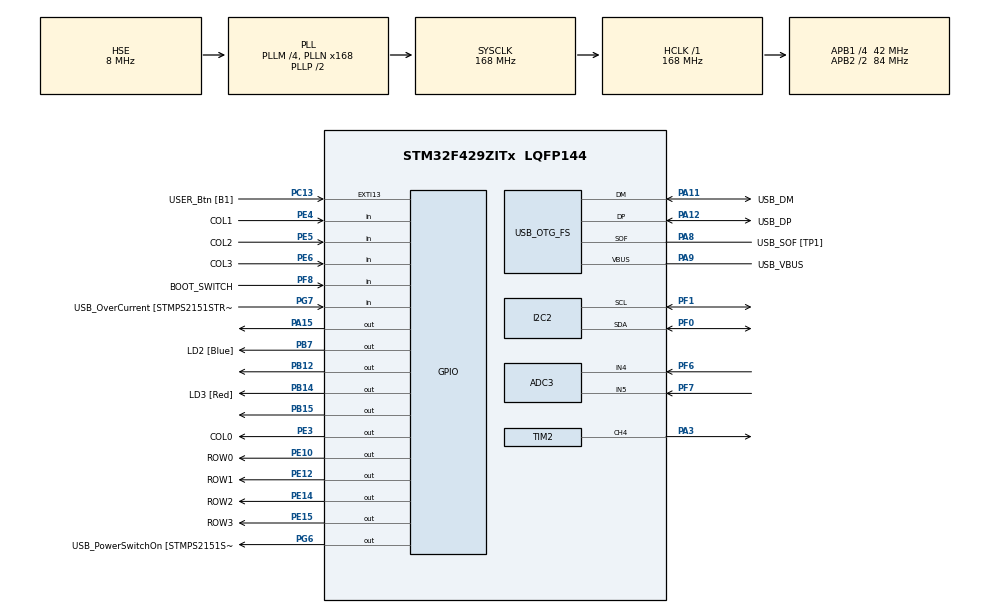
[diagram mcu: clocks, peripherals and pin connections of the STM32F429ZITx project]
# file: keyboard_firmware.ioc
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ADC3.Channel-0\#ChannelRegularConversion=ADC_CHANNEL_5
ADC3.NbrOfConversionFlag=1
ADC3.Rank-0\#ChannelRegularConversion=1
ADC3.SamplingTime-0\#ChannelRegularConversion=ADC_SAMPLETIME_3CYCLES
Dma.Request0=TIM2_CH2/CH4
Dma.TIM2_CH2/CH4.0.Direction=DMA_MEMORY_TO_PERIPH
Dma.TIM2_CH2/CH4.0.FIFOMode=DMA_FIFOMODE_DISABLE
Dma.TIM2_CH2/CH4.0.Instance=DMA1_Stream6
Dma.TIM2_CH2/CH4.0.MemDataAlignment=DMA_MDATAALIGN_WORD
Dma.TIM2_CH2/CH4.0.MemInc=DMA_MINC_ENABLE
Dma.TIM2_CH2/CH4.0.Mode=DMA_CIRCULAR
Dma.TIM2_CH2/CH4.0.PeriphDataAlignment=DMA_PDATAALIGN_WORD
Dma.TIM2_CH2/CH4.0.PeriphInc=DMA_PINC_DISABLE
Dma.TIM2_CH2/CH4.0.Priority=DMA_PRIORITY_MEDIUM
FREERTOS.INCLUDE_vTaskDelayUntil=1
FREERTOS.Tasks01=defaultTask,0,128,StartDefaultTask,Default,NULL,Dynamic,NULL,NULL
FREERTOS.configUSE_NEWLIB_REENTRANT=1
FREERTOS.configUSE_TIMERS=1
Mcu.Family=STM32F4
Mcu.Name=STM32F429ZITx
Mcu.Package=LQFP144
NVIC.DMA1_Stream6_IRQn=true\:5\:0\:false\:false\:true\:true\:false\:true\:true
NVIC.OTG_FS_IRQn=true\:5\:0\:false\:false\:true\:true\:true\:true\:true
NVIC.PriorityGroup=NVIC_PRIORITYGROUP_4
NVIC.TIM4_IRQn=true\:0\:0\:false\:false\:true\:false\:true\:true\:true
NVIC.TimeBase=TIM4_IRQn
NVIC.TimeBaseIP=TIM4
PA1.Signal=ETH_REF_CLK
PA10.GPIO_Label=USB_ID
PA10.Signal=USB_OTG_FS_ID
PA11.GPIO_Label=USB_DM
PA11.Mode=Device_Only
PA11.Signal=USB_OTG_FS_DM
PA12.GPIO_Label=USB_DP
PA12.Mode=Device_Only
PA12.Signal=USB_OTG_FS_DP
PA13.GPIO_Label=TMS
PA13.Mode=Serial_Wire
PA13.Signal=SYS_JTMS-SWDIO
PA14.GPIO_Label=TCK
PA14.Mode=Serial_Wire
PA14.Signal=SYS_JTCK-SWCLK
PA15.Signal=GPIO_Output
PA2.GPIO_Label=RMII_MDIO [LAN8742A-CZ-TR_MDIO]
PA2.Signal=ETH_MDIO
PA3.Signal=S_TIM2_CH4
PA7.Signal=ETH_CRS_DV
PA8.GPIO_Label=USB_SOF [TP1]
PA8.Mode=Activate_SOF_FS
PA8.Signal=USB_OTG_FS_SOF
PA9.GPIO_Label=USB_VBUS
PA9.Mode=Activate_VBUS
PA9.Signal=USB_OTG_FS_VBUS
PB12.Signal=GPIO_Output
PB13.GPIO_Label=RMII_TXD1 [LAN8742A-CZ-TR_TXD1]
PB13.Signal=ETH_TXD1
PB14.GPIO_Label=LD3 [Red]
PB14.Signal=GPIO_Output
PB15.Signal=GPIO_Output
PB7.GPIO_Label=LD2 [Blue]
PB7.Signal=GPIO_Output
PC1.GPIO_Label=RMII_MDC [LAN8742A-CZ-TR_MDC]
PC1.Signal=ETH_MDC
PC13.GPIO_Label=USER_Btn [B1]
PC13.Signal=GPXTI13
PC14/OSC32_IN.Mode=LSE-External-Oscillator
PC14/OSC32_IN.Signal=RCC_OSC32_IN
PC15/OSC32_OUT.Mode=LSE-External-Oscillator
PC15/OSC32_OUT.Signal=RCC_OSC32_OUT
PC4.GPIO_Label=RMII_RXD0 [LAN8742A-CZ-TR_RXD0]
PC4.Signal=ETH_RXD0
PC5.GPIO_Label=RMII_RXD1 [LAN8742A-CZ-TR_RXD1]
PC5.Signal=ETH_RXD1
PD8.GPIO_Label=STLK_RX [STM32F103CBT6_PA3]
PD8.Signal=USART3_TX
PD9.GPIO_Label=STLK_TX [STM32F103CBT6_PA2]
PD9.Signal=USART3_RX
PE10.GPIO_Label=ROW0
PE10.Signal=GPIO_Output
PE12.GPIO_Label=ROW1
PE12.Signal=GPIO_Output
PE14.GPIO_Label=ROW2
PE14.Signal=GPIO_Output
PE15.GPIO_Label=ROW3
PE15.Signal=GPIO_Output
PE3.GPIO_Label=COL0
PE3.Signal=GPIO_Output
PE4.GPIO_Label=COL1
PE4.GPIO_PuPd=GPIO_PULLDOWN
PE4.Signal=GPIO_Input
PE5.GPIO_Label=COL2
PE5.GPIO_PuPd=GPIO_PULLDOWN
PE5.Signal=GPIO_Input
PE6.GPIO_Label=COL3
PE6.GPIO_PuPd=GPIO_PULLDOWN
PE6.Signal=GPIO_Input
PF0.GPIO_Pu=GPIO_PULLUP
PF0.Mode=I2C
PF0.Signal=I2C2_SDA
PF1.GPIO_Pu=GPIO_PULLUP
PF1.Mode=I2C
PF1.Signal=I2C2_SCL
PF6.Mode=IN4
PF6.Signal=ADC3_IN4
PF7.Mode=IN5
PF7.Signal=ADC3_IN5
PF8.GPIO_Label=BOOT_SWITCH
PF8.Signal=GPIO_Input
PG11.GPIO_Label=RMII_TX_EN [LAN8742A-CZ-TR_TXEN]
PG11.Signal=ETH_TX_EN
PG13.GPIO_Label=RMII_TXD0 [LAN8742A-CZ-TR_TXD0]
PG13.Signal=ETH_TXD0
PG6.GPIO_Label=USB_PowerSwitchOn [STMPS2151STR_EN]
PG6.Signal=GPIO_Output
PG7.GPIO_Label=USB_OverCurrent [STMPS2151STR_FAULT]
PG7.Signal=GPIO_Input
PH0/OSC_IN.GPIO_Label=MCO [STM32F103CBT6_PA8]
PH0/OSC_IN.Mode=HSE-External-Clock-Source
PH0/OSC_IN.Signal=RCC_OSC_IN
PH1/OSC_OUT.Mode=HSE-External-Clock-Source
PH1/OSC_OUT.Signal=RCC_OSC_OUT
ProjectManager.HeapSize=0x200
ProjectManager.StackSize=0x400
ProjectManager.TargetToolchain=STM32CubeIDE
RCC.48MHZClocksFreq_Value=48000000
RCC.AHBFreq_Value=168000000
RCC.APB1CLKDivider=RCC_HCLK_DIV4
RCC.APB1Freq_Value=42000000
RCC.APB1TimFreq_Value=84000000
RCC.APB2CLKDivider=RCC_HCLK_DIV2
RCC.APB2Freq_Value=84000000
RCC.APB2TimFreq_Value=168000000
RCC.CortexFreq_Value=168000000
RCC.HCLKFreq_Value=168000000
RCC.HSE_VALUE=8000000
RCC.HSI_VALUE=16000000
RCC.PLLM=4
RCC.PLLMUL=RCC_PLL_MUL9
RCC.PLLN=168
RCC.PLLQ=7
RCC.PRESCALERUSB=RCC_USBCLKSOURCE_PLL_DIV1_5
RCC.SYSCLKFreq_VALUE=168000000
RCC.SYSCLKSource=RCC_SYSCLKSOURCE_PLLCLK
RCC.SYSCLKSourceVirtual=RCC_SYSCLKSOURCE_PLLCLK
RCC.USBFreq_Value=48000000
RCC.VCOOutputFreq_Value=336000000
SH.S_TIM2_CH4.0=TIM2_CH4,PWM Generation4 CH4
TIM2.AutoReloadPreload=TIM_AUTORELOAD_PRELOAD_ENABLE
TIM2.Channel-PWM\ Generation4\ CH4=TIM_CHANNEL_4
TIM2.OCMode_PWM-PWM\ Generation4\ CH4=TIM_OCMODE_PWM1
TIM2.Period=204
USB_DEVICE.CLASS_NAME_FS=HID
USB_DEVICE.PRODUCT_STRING_HID_FS=STM32 Mech Keyboard
USB_DEVICE.USBD_SUPPORT_USER_STRING-HID_FS=1
USB_DEVICE.VirtualMode-HID_FS=Hid
USB_DEVICE.VirtualModeFS=Hid_FS
USB_OTG_FS.VirtualMode=Device_Only
VP_FREERTOS_VS_CMSIS_V1.Mode=CMSIS_V1
VP_SYS_VS_tim4.Mode=TIM4
VP_TIM2_VS_ClockSourceINT.Mode=Internal
VP_USB_DEVICE_VS_USB_DEVICE_HID_FS.Mode=HID_FS
board=NUCLEO-F429ZI

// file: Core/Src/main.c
/* USER CODE BEGIN Header */
/**
 ******************************************************************************
 * @file           : main.c
 * @brief          : Main program body
 ******************************************************************************
 * @attention
 *
 * Copyright (c) 2022 STMicroelectronics.
 * All rights reserved.
 *
 * This software is licensed under terms that can be found in the LICENSE file
 * in the root directory of this software component.
 * If no LICENSE file comes with this software, it is provided AS-IS.
 *
 ******************************************************************************
 */
/* USER CODE END Header */
#include "main.h"
#include "cmsis_os.h"
#include "usb_device.h"

/* USER CODE BEGIN Includes */
#include "keyboard.h"
#include "send.h"
#include "keymap.h"
/* USER CODE END Includes */

 ADC_HandleTypeDef hadc3;

I2C_HandleTypeDef hi2c2;

TIM_HandleTypeDef htim2;
DMA_HandleTypeDef hdma_tim2_ch2_ch4;

osThreadId defaultTaskHandle;

void SystemClock_Config(void);
static void MX_GPIO_Init(void);
static void MX_I2C2_Init(void);
static void MX_DMA_Init(void);
static void MX_TIM2_Init(void);
static void MX_ADC3_Init(void);
void StartDefaultTask(void const * argument);

/* USER CODE BEGIN 0 */

void XferHalfCpltCallback(struct __DMA_HandleTypeDef *hdma) {

}
void XferCpltCallback(struct __DMA_HandleTypeDef *hdma) {
}

void send_rgb(void) {
//	HAL_DMA_Start();
}
/* USER CODE END 0 */

int main(void)
{

  /* MCU Configuration--------------------------------------------------------*/

  /* Reset of all peripherals, Initializes the Flash interface and the Systick. */
  HAL_Init();

  /* Configure the system clock */
  SystemClock_Config();

  /* Initialize all configured peripherals */
  MX_GPIO_Init();
  MX_I2C2_Init();
  MX_DMA_Init();
  MX_TIM2_Init();
  MX_ADC3_Init();
  /* USER CODE BEGIN 2 */

	// Register DMA callbacks
	HAL_DMA_RegisterCallback(&hdma_tim2_ch2_ch4, HAL_DMA_XFER_CPLT_CB_ID,
			XferCpltCallback);
	HAL_DMA_RegisterCallback(&hdma_tim2_ch2_ch4, HAL_DMA_XFER_HALFCPLT_CB_ID,
			XferHalfCpltCallback);

	keyboardInit();
	sendInit();
	keymapInit();
  /* USER CODE END 2 */

  /* Create the thread(s) */
  /* definition and creation of defaultTask */
  osThreadDef(defaultTask, StartDefaultTask, osPriorityNormal, 0, 128);
  defaultTaskHandle = osThreadCreate(osThread(defaultTask), NULL);

  /* Start scheduler */
  osKernelStart();

  /* We should never get here as control is now taken by the scheduler */
  /* Infinite loop */
	while (1) {

	}
}

void SystemClock_Config(void)
{
  RCC_OscInitTypeDef RCC_OscInitStruct = {0};
  RCC_ClkInitTypeDef RCC_ClkInitStruct = {0};

  /** Configure the main internal regulator output voltage
  */
  __HAL_RCC_PWR_CLK_ENABLE();
  __HAL_PWR_VOLTAGESCALING_CONFIG(PWR_REGULATOR_VOLTAGE_SCALE1);

  /** Initializes the RCC Oscillators according to the specified parameters
  * in the RCC_OscInitTypeDef structure.
  */
  RCC_OscInitStruct.OscillatorType = RCC_OSCILLATORTYPE_HSE;
  RCC_OscInitStruct.HSEState = RCC_HSE_BYPASS;
  RCC_OscInitStruct.PLL.PLLState = RCC_PLL_ON;
  RCC_OscInitStruct.PLL.PLLSource = RCC_PLLSOURCE_HSE;
  RCC_OscInitStruct.PLL.PLLM = 4;
  RCC_OscInitStruct.PLL.PLLN = 168;
  RCC_OscInitStruct.PLL.PLLP = RCC_PLLP_DIV2;
  RCC_OscInitStruct.PLL.PLLQ = 7;
  if (HAL_RCC_OscConfig(&RCC_OscInitStruct) != HAL_OK)
  {
    Error_Handler();
  }

  /** Initializes the CPU, AHB and APB buses clocks
  */
  RCC_ClkInitStruct.ClockType = RCC_CLOCKTYPE_HCLK|RCC_CLOCKTYPE_SYSCLK
                              |RCC_CLOCKTYPE_PCLK1|RCC_CLOCKTYPE_PCLK2;
  RCC_ClkInitStruct.SYSCLKSource = RCC_SYSCLKSOURCE_PLLCLK;
  RCC_ClkInitStruct.AHBCLKDivider = RCC_SYSCLK_DIV1;
  RCC_ClkInitStruct.APB1CLKDivider = RCC_HCLK_DIV4;
  RCC_ClkInitStruct.APB2CLKDivider = RCC_HCLK_DIV2;

  if (HAL_RCC_ClockConfig(&RCC_ClkInitStruct, FLASH_LATENCY_5) != HAL_OK)
  {
    Error_Handler();
  }
}

static void MX_ADC3_Init(void)
{

  ADC_ChannelConfTypeDef sConfig = {0};

  /** Configure the global features of the ADC (Clock, Resolution, Data Alignment and number of conversion)
  */
  hadc3.Instance = ADC3;
  hadc3.Init.ClockPrescaler = ADC_CLOCK_SYNC_PCLK_DIV4;
  hadc3.Init.Resolution = ADC_RESOLUTION_12B;
  hadc3.Init.ScanConvMode = DISABLE;
  hadc3.Init.ContinuousConvMode = DISABLE;
  hadc3.Init.DiscontinuousConvMode = DISABLE;
  hadc3.Init.ExternalTrigConvEdge = ADC_EXTERNALTRIGCONVEDGE_NONE;
  hadc3.Init.ExternalTrigConv = ADC_SOFTWARE_START;
  hadc3.Init.DataAlign = ADC_DATAALIGN_RIGHT;
  hadc3.Init.NbrOfConversion = 1;
  hadc3.Init.DMAContinuousRequests = DISABLE;
  hadc3.Init.EOCSelection = ADC_EOC_SINGLE_CONV;
  if (HAL_ADC_Init(&hadc3) != HAL_OK)
  {
    Error_Handler();
  }

  /** Configure for the selected ADC regular channel its corresponding rank in the sequencer and its sample time.
  */
  sConfig.Channel = ADC_CHANNEL_5;
  sConfig.Rank = 1;
  sConfig.SamplingTime = ADC_SAMPLETIME_3CYCLES;
  if (HAL_ADC_ConfigChannel(&hadc3, &sConfig) != HAL_OK)
  {
    Error_Handler();
  }

}

static void MX_I2C2_Init(void)
{

  hi2c2.Instance = I2C2;
  hi2c2.Init.ClockSpeed = 100000;
  hi2c2.Init.DutyCycle = I2C_DUTYCYCLE_2;
  hi2c2.Init.OwnAddress1 = 0;
  hi2c2.Init.AddressingMode = I2C_ADDRESSINGMODE_7BIT;
  hi2c2.Init.DualAddressMode = I2C_DUALADDRESS_DISABLE;
  hi2c2.Init.OwnAddress2 = 0;
  hi2c2.Init.GeneralCallMode = I2C_GENERALCALL_DISABLE;
  hi2c2.Init.NoStretchMode = I2C_NOSTRETCH_DISABLE;
  if (HAL_I2C_Init(&hi2c2) != HAL_OK)
  {
    Error_Handler();
  }

  /** Configure Analogue filter
  */
  if (HAL_I2CEx_ConfigAnalogFilter(&hi2c2, I2C_ANALOGFILTER_ENABLE) != HAL_OK)
  {
    Error_Handler();
  }

  /** Configure Digital filter
  */
  if (HAL_I2CEx_ConfigDigitalFilter(&hi2c2, 0) != HAL_OK)
  {
    Error_Handler();
  }

}

static void MX_TIM2_Init(void)
{

  TIM_ClockConfigTypeDef sClockSourceConfig = {0};
  TIM_MasterConfigTypeDef sMasterConfig = {0};
  TIM_OC_InitTypeDef sConfigOC = {0};

  htim2.Instance = TIM2;
  htim2.Init.Prescaler = 0;
  htim2.Init.CounterMode = TIM_COUNTERMODE_UP;
  htim2.Init.Period = 204;
  htim2.Init.ClockDivision = TIM_CLOCKDIVISION_DIV1;
  htim2.Init.AutoReloadPreload = TIM_AUTORELOAD_PRELOAD_ENABLE;
  if (HAL_TIM_Base_Init(&htim2) != HAL_OK)
  {
    Error_Handler();
  }
  sClockSourceConfig.ClockSource = TIM_CLOCKSOURCE_INTERNAL;
  if (HAL_TIM_ConfigClockSource(&htim2, &sClockSourceConfig) != HAL_OK)
  {
    Error_Handler();
  }
  if (HAL_TIM_PWM_Init(&htim2) != HAL_OK)
  {
    Error_Handler();
  }
  sMasterConfig.MasterOutputTrigger = TIM_TRGO_RESET;
  sMasterConfig.MasterSlaveMode = TIM_MASTERSLAVEMODE_DISABLE;
  if (HAL_TIMEx_MasterConfigSynchronization(&htim2, &sMasterConfig) != HAL_OK)
  {
    Error_Handler();
  }
  sConfigOC.OCMode = TIM_OCMODE_PWM1;
  sConfigOC.Pulse = 0;
  sConfigOC.OCPolarity = TIM_OCPOLARITY_HIGH;
  sConfigOC.OCFastMode = TIM_OCFAST_DISABLE;
  if (HAL_TIM_PWM_ConfigChannel(&htim2, &sConfigOC, TIM_CHANNEL_4) != HAL_OK)
  {
    Error_Handler();
  }
  HAL_TIM_MspPostInit(&htim2);

}

static void MX_DMA_Init(void)
{

  /* DMA controller clock enable */
  __HAL_RCC_DMA1_CLK_ENABLE();

  /* DMA interrupt init */
  /* DMA1_Stream6_IRQn interrupt configuration */
  HAL_NVIC_SetPriority(DMA1_Stream6_IRQn, 5, 0);
  HAL_NVIC_EnableIRQ(DMA1_Stream6_IRQn);

}

static void MX_GPIO_Init(void)
{
  GPIO_InitTypeDef GPIO_InitStruct = {0};

  /* GPIO Ports Clock Enable */
  __HAL_RCC_GPIOE_CLK_ENABLE();
  __HAL_RCC_GPIOC_CLK_ENABLE();
  __HAL_RCC_GPIOF_CLK_ENABLE();
  __HAL_RCC_GPIOH_CLK_ENABLE();
  __HAL_RCC_GPIOA_CLK_ENABLE();
  __HAL_RCC_GPIOB_CLK_ENABLE();
  __HAL_RCC_GPIOD_CLK_ENABLE();
  __HAL_RCC_GPIOG_CLK_ENABLE();

  /*Configure GPIO pin Output Level */
  HAL_GPIO_WritePin(GPIOE, COL0_Pin|ROW0_Pin|ROW1_Pin|ROW2_Pin
                          |ROW3_Pin, GPIO_PIN_RESET);

  /*Configure GPIO pin Output Level */
  HAL_GPIO_WritePin(GPIOB, GPIO_PIN_12|LD3_Pin|GPIO_PIN_15|LD2_Pin, GPIO_PIN_RESET);

  /*Configure GPIO pin Output Level */
  HAL_GPIO_WritePin(USB_PowerSwitchOn_GPIO_Port, USB_PowerSwitchOn_Pin, GPIO_PIN_RESET);

  /*Configure GPIO pin Output Level */
  HAL_GPIO_WritePin(GPIOA, GPIO_PIN_15, GPIO_PIN_RESET);

  /*Configure GPIO pins : COL0_Pin ROW0_Pin ROW1_Pin ROW2_Pin
                           ROW3_Pin */
  GPIO_InitStruct.Pin = COL0_Pin|ROW0_Pin|ROW1_Pin|ROW2_Pin
                          |ROW3_Pin;
  GPIO_InitStruct.Mode = GPIO_MODE_OUTPUT_PP;
  GPIO_InitStruct.Pull = GPIO_NOPULL;
  GPIO_InitStruct.Speed = GPIO_SPEED_FREQ_LOW;
  HAL_GPIO_Init(GPIOE, &GPIO_InitStruct);

  /*Configure GPIO pins : COL1_Pin COL2_Pin COL3_Pin */
  GPIO_InitStruct.Pin = COL1_Pin|COL2_Pin|COL3_Pin;
  GPIO_InitStruct.Mode = GPIO_MODE_INPUT;
  GPIO_InitStruct.Pull = GPIO_PULLDOWN;
  HAL_GPIO_Init(GPIOE, &GPIO_InitStruct);

  /*Configure GPIO pin : USER_Btn_Pin */
  GPIO_InitStruct.Pin = USER_Btn_Pin;
  GPIO_InitStruct.Mode = GPIO_MODE_IT_RISING;
  GPIO_InitStruct.Pull = GPIO_NOPULL;
  HAL_GPIO_Init(USER_Btn_GPIO_Port, &GPIO_InitStruct);

  /*Configure GPIO pin : BOOT_SWITCH_Pin */
  GPIO_InitStruct.Pin = BOOT_SWITCH_Pin;
  GPIO_InitStruct.Mode = GPIO_MODE_INPUT;
  GPIO_InitStruct.Pull = GPIO_NOPULL;
  HAL_GPIO_Init(BOOT_SWITCH_GPIO_Port, &GPIO_InitStruct);

  /*Configure GPIO pins : RMII_MDC_Pin RMII_RXD0_Pin RMII_RXD1_Pin */
  GPIO_InitStruct.Pin = RMII_MDC_Pin|RMII_RXD0_Pin|RMII_RXD1_Pin;
  GPIO_InitStruct.Mode = GPIO_MODE_AF_PP;
  GPIO_InitStruct.Pull = GPIO_NOPULL;
  GPIO_InitStruct.Speed = GPIO_SPEED_FREQ_VERY_HIGH;
  GPIO_InitStruct.Alternate = GPIO_AF11_ETH;
  HAL_GPIO_Init(GPIOC, &GPIO_InitStruct);

  /*Configure GPIO pins : PA1 RMII_MDIO_Pin PA7 */
  GPIO_InitStruct.Pin = GPIO_PIN_1|RMII_MDIO_Pin|GPIO_PIN_7;
  GPIO_InitStruct.Mode = GPIO_MODE_AF_PP;
  GPIO_InitStruct.Pull = GPIO_NOPULL;
  GPIO_InitStruct.Speed = GPIO_SPEED_FREQ_VERY_HIGH;
  GPIO_InitStruct.Alternate = GPIO_AF11_ETH;
  HAL_GPIO_Init(GPIOA, &GPIO_InitStruct);

  /*Configure GPIO pins : PB12 LD3_Pin PB15 LD2_Pin */
  GPIO_InitStruct.Pin = GPIO_PIN_12|LD3_Pin|GPIO_PIN_15|LD2_Pin;
  GPIO_InitStruct.Mode = GPIO_MODE_OUTPUT_PP;
  GPIO_InitStruct.Pull = GPIO_NOPULL;
  GPIO_InitStruct.Speed = GPIO_SPEED_FREQ_LOW;
  HAL_GPIO_Init(GPIOB, &GPIO_InitStruct);

  /*Configure GPIO pin : RMII_TXD1_Pin */
  GPIO_InitStruct.Pin = RMII_TXD1_Pin;
  GPIO_InitStruct.Mode = GPIO_MODE_AF_PP;
  GPIO_InitStruct.Pull = GPIO_NOPULL;
  GPIO_InitStruct.Speed = GPIO_SPEED_FREQ_VERY_HIGH;
  GPIO_InitStruct.Alternate = GPIO_AF11_ETH;
  HAL_GPIO_Init(RMII_TXD1_GPIO_Port, &GPIO_InitStruct);

  /*Configure GPIO pins : STLK_RX_Pin STLK_TX_Pin */
  GPIO_InitStruct.Pin = STLK_RX_Pin|STLK_TX_Pin;
  GPIO_InitStruct.Mode = GPIO_MODE_AF_PP;
  GPIO_InitStruct.Pull = GPIO_NOPULL;
  GPIO_InitStruct.Speed = GPIO_SPEED_FREQ_VERY_HIGH;
  GPIO_InitStruct.Alternate = GPIO_AF7_USART3;
  HAL_GPIO_Init(GPIOD, &GPIO_InitStruct);

  /*Configure GPIO pin : USB_PowerSwitchOn_Pin */
  GPIO_InitStruct.Pin = USB_PowerSwitchOn_Pin;
  GPIO_InitStruct.Mode = GPIO_MODE_OUTPUT_PP;
  GPIO_InitStruct.Pull = GPIO_NOPULL;
  GPIO_InitStruct.Speed = GPIO_SPEED_FREQ_LOW;
  HAL_GPIO_Init(USB_PowerSwitchOn_GPIO_Port, &GPIO_InitStruct);

  /*Configure GPIO pin : USB_OverCurrent_Pin */
  GPIO_InitStruct.Pin = USB_OverCurrent_Pin;
  GPIO_InitStruct.Mode = GPIO_MODE_INPUT;
  GPIO_InitStruct.Pull = GPIO_NOPULL;
  HAL_GPIO_Init(USB_OverCurrent_GPIO_Port, &GPIO_InitStruct);

  /*Configure GPIO pin : PA15 */
  GPIO_InitStruct.Pin = GPIO_PIN_15;
  GPIO_InitStruct.Mode = GPIO_MODE_OUTPUT_PP;
  GPIO_InitStruct.Pull = GPIO_NOPULL;
  GPIO_InitStruct.Speed = GPIO_SPEED_FREQ_LOW;
  HAL_GPIO_Init(GPIOA, &GPIO_InitStruct);

  /*Configure GPIO pins : RMII_TX_EN_Pin RMII_TXD0_Pin */
  GPIO_InitStruct.Pin = RMII_TX_EN_Pin|RMII_TXD0_Pin;
  GPIO_InitStruct.Mode = GPIO_MODE_AF_PP;
  GPIO_InitStruct.Pull = GPIO_NOPULL;
  GPIO_InitStruct.Speed = GPIO_SPEED_FREQ_VERY_HIGH;
  GPIO_InitStruct.Alternate = GPIO_AF11_ETH;
  HAL_GPIO_Init(GPIOG, &GPIO_InitStruct);

}

void StartDefaultTask(void const * argument)
{
  /* init code for USB_DEVICE */
  MX_USB_DEVICE_Init();
	for (;;) {
		osDelay(1);
	}
}

void HAL_TIM_PeriodElapsedCallback(TIM_HandleTypeDef *htim)
{
  /* USER CODE BEGIN Callback 0 */
//
  /* USER CODE END Callback 0 */
  if (htim->Instance == TIM4) {
    HAL_IncTick();
  }
  /* USER CODE BEGIN Callback 1 */
//
  /* USER CODE END Callback 1 */
}

void Error_Handler(void)
{
	__disable_irq();
	while (1) {
	}
}

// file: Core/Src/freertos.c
/* USER CODE BEGIN Header */
/**
 ******************************************************************************
 * File Name          : freertos.c
 * Description        : Code for freertos applications
 ******************************************************************************
 * @attention
 *
 * Copyright (c) 2022 STMicroelectronics.
 * All rights reserved.
 *
 * This software is licensed under terms that can be found in the LICENSE file
 * in the root directory of this software component.
 * If no LICENSE file comes with this software, it is provided AS-IS.
 *
 ******************************************************************************
 */
/* USER CODE END Header */

#include "FreeRTOS.h"
#include "task.h"
#include "main.h"

/* GetIdleTaskMemory prototype (linked to static allocation support) */
void vApplicationGetIdleTaskMemory( StaticTask_t **ppxIdleTaskTCBBuffer, StackType_t **ppxIdleTaskStackBuffer, uint32_t *pulIdleTaskStackSize );

/* GetTimerTaskMemory prototype (linked to static allocation support) */
void vApplicationGetTimerTaskMemory( StaticTask_t **ppxTimerTaskTCBBuffer, StackType_t **ppxTimerTaskStackBuffer, uint32_t *pulTimerTaskStackSize );

/* USER CODE BEGIN GET_IDLE_TASK_MEMORY */
static StaticTask_t xIdleTaskTCBBuffer;
static StackType_t xIdleStack[configMINIMAL_STACK_SIZE];

void vApplicationGetIdleTaskMemory(StaticTask_t **ppxIdleTaskTCBBuffer,
		StackType_t **ppxIdleTaskStackBuffer, uint32_t *pulIdleTaskStackSize) {
	*ppxIdleTaskTCBBuffer = &xIdleTaskTCBBuffer;
	*ppxIdleTaskStackBuffer = &xIdleStack[0];
	*pulIdleTaskStackSize = configMINIMAL_STACK_SIZE;
	/* place for user code */
}
/* USER CODE END GET_IDLE_TASK_MEMORY */

/* USER CODE BEGIN GET_TIMER_TASK_MEMORY */
static StaticTask_t xTimerTaskTCBBuffer;
static StackType_t xTimerStack[configTIMER_TASK_STACK_DEPTH];

void vApplicationGetTimerTaskMemory(StaticTask_t **ppxTimerTaskTCBBuffer,
		StackType_t **ppxTimerTaskStackBuffer, uint32_t *pulTimerTaskStackSize) {
	*ppxTimerTaskTCBBuffer = &xTimerTaskTCBBuffer;
	*ppxTimerTaskStackBuffer = &xTimerStack[0];
	*pulTimerTaskStackSize = configTIMER_TASK_STACK_DEPTH;
	/* place for user code */
}
/* USER CODE END GET_TIMER_TASK_MEMORY */
